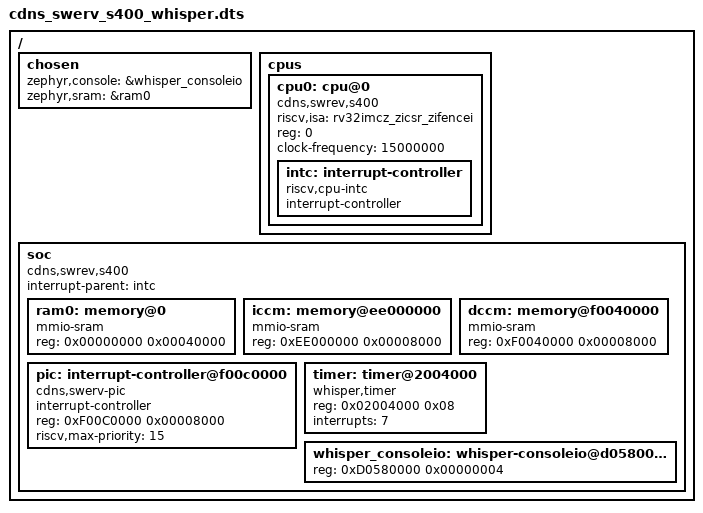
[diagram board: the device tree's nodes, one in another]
/*
 * Copyright (C) 2024 Intel Corporation
 *
 * SPDX-License-Identifier: Apache-2.0
 */

/dts-v1/;

#include <skeleton.dtsi>

/ {
	#address-cells = <1>;
	#size-cells = <1>;

	chosen {
		zephyr,console = &whisper_consoleio;
		zephyr,sram = &ram0;
	};

	cpus {
		#address-cells = <1>;
		#size-cells = <0>;
		cpu0: cpu@0 {
			device_type = "cpu";
			compatible = "cdns,swrev,s400", "riscv";
			riscv,isa = "rv32imcz_zicsr_zifencei";
			reg = <0>;
			clock-frequency = <15000000>;

			intc: interrupt-controller {
				compatible = "riscv,cpu-intc";
				#address-cells = <0>;
				#interrupt-cells = <1>;
				interrupt-controller;
			};
		};
	};

	soc {
		#address-cells = <1>;
		#size-cells = <1>;
		compatible = "cdns,swrev,s400", "simple-bus";
		interrupt-parent = <&intc>;
		ranges;

		ram0: memory@0 {
			compatible = "mmio-sram";
			reg = <0x00000000 0x00040000>;
		};

		iccm: memory@ee000000 {
			compatible = "mmio-sram";
			reg = <0xEE000000 0x00008000>;
		};

		dccm: memory@f0040000 {
			compatible = "mmio-sram";
			reg = <0xF0040000 0x00008000>;
		};

		pic: interrupt-controller@f00c0000 {
			compatible = "cdns,swerv-pic";
			#address-cells = <1>;
			#interrupt-cells = <2>;
			interrupt-controller;
			reg = <0xF00C0000 0x00008000>;
			riscv,max-priority = <15>;
		};

		timer: timer@2004000 {
			compatible = "whisper,timer";
			reg = <0x02004000 0x08>;
			interrupts = <7>;
		};

		whisper_consoleio: whisper-consoleio@d0580000 {
			reg = <0xD0580000 0x00000004>;

			status = "okay";
		};
	};
};
